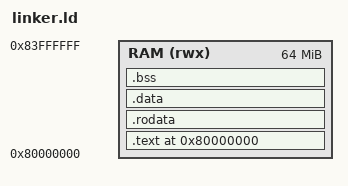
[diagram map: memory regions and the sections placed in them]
OUTPUT_ARCH(riscv)
ENTRY(_start)

MEMORY {
  RAM (rwx) : ORIGIN = 0x80000000, LENGTH = 64M
}

SECTIONS {
  . = ORIGIN(RAM);

  .text : ALIGN(4) {
    KEEP(*(.text.init))
    *(.text .text.*)
  } > RAM

  .rodata : ALIGN(8) {
    *(.rodata .rodata.*)
  } > RAM

  .data : ALIGN(8) {
    *(.data .data.*)
    *(.sdata .sdata.*)
  } > RAM

  .bss (NOLOAD) : ALIGN(8) {
    __bss_start = .;
    *(.sbss .sbss.*)
    *(.bss .bss.*)
    *(COMMON)
    . = ALIGN(8);
    __bss_end = .;
  } > RAM

  . = ALIGN(16);
  __image_end = .;
  __stack_top = ORIGIN(RAM) + 0x00100000;

  /DISCARD/ : {
    *(.comment)
    *(.note*)
    *(.eh_frame*)
    *(.riscv.attributes)
  }
}

ASSERT(__image_end < (__stack_top - 0x1000), "compiled workload overlaps the stack")
